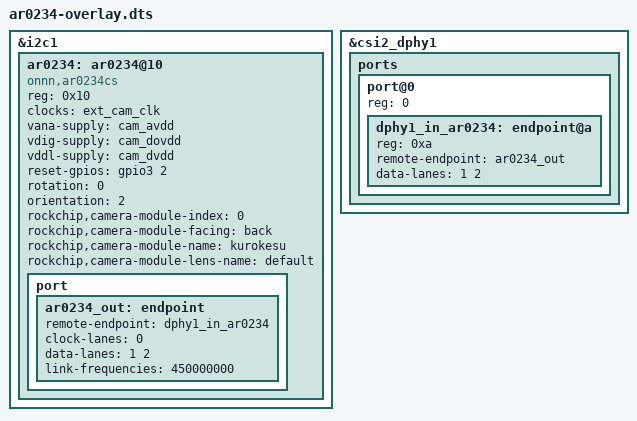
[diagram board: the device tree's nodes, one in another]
// SPDX-License-Identifier: GPL-2.0-only
/*
 * AR0234 (Kurokesu) on the LubanCat CSI0 connector - first bring-up overlay.
 *
 * Modelled on rk356x-lubancat-csi0-ov8858-1632x1224-30fps-overlay.dts, but
 * based on what rk3568-lubancat-csi2.dtsi really contains:
 *
 *   CSI0 = &i2c1 -> sensor -> &csi2_dphy1 (port@0, split mode, 2 lanes) -> rkisp_vir0
 *
 * Variant for the "csi2-double" dtsi (csi2_dphy0 disabled, csi2_dphy1 used).
 * For the single-camera dtsi use the overlay that targets &csi2_dphy0.
 *
 * A NEW sensor node is created instead of re-using the &ov8858 node, because
 * that node carries "lens-focus = <&dw9714>", which would make the sensor's
 * async notifier wait for a lens driver that this camera does not have.
 *
 * Labels referenced from the base device tree (all present in the dtsi):
 *   &i2c1 &csi2_dphy1 &ext_cam_clk &cam_avdd &cam_dovdd &cam_dvdd &gpio3
 *
 * Not verified on hardware.
 */
/dts-v1/;
/plugin/;

/ {
	fragment@0 {
		target = <&i2c1>;
		__overlay__ {
			/* Same values as the base i2c1 node; tells dtc that
			 * child "reg" is a 1-cell I2C address */
			#address-cells = <1>;
			#size-cells = <0>;
			status = "okay";

			ar0234: ar0234@10 {
				compatible = "onnn,ar0234cs";
				status = "okay";
				reg = <0x10>;

				/* 24 MHz fixed clock defined in the base dtsi */
				clocks = <&ext_cam_clk>;
				clock-names = "xvclk";

				/*
				 * Same rails the OV8858 node uses:
				 * avdd 2.8 V, dovdd 1.8 V, dvdd 1.2 V.
				 */
				vana-supply = <&cam_avdd>;
				vdig-supply = <&cam_dovdd>;
				vddl-supply = <&cam_dvdd>;

				/*
				 * Pin 11 of the 15-pin connector (CAM_IO0) is the
				 * module power enable and is wired to the board's
				 * CAM0_PWDN net. The driver drives its "reset" GPIO
				 * high while the sensor is powered, which is the
				 * level the module needs.
				 *
				 * <&gpio3 2 0> = GPIO3_A2, active high
				 * (2 = RK_PA2, 0 = GPIO_ACTIVE_HIGH; numbers are
				 * used because this overlay is built without the
				 * kernel include files).
				 * GPIO3_A2 = CAM0_PWDN, from the board schematic.
				 */
				reset-gpios = <&gpio3 2 0>;

				rotation = <0>;
				orientation = <2>;

				/* Rockchip module information (mandatory) */
				rockchip,camera-module-index = <0>;
				rockchip,camera-module-facing = "back";
				rockchip,camera-module-name = "kurokesu";
				rockchip,camera-module-lens-name = "default";

				port {
					ar0234_out: endpoint {
						remote-endpoint = <&dphy1_in_ar0234>;
						clock-lanes = <0>;
						data-lanes = <1 2>;
						/*
						 * The FIRST value selects the
						 * driver configuration:
						 *   450000000 -> 10-bit
						 *   360000000 ->  8-bit
						 */
						link-frequencies =
							/bits/ 64 <450000000>;
					};
				};
			};
		};
	};

	fragment@1 {
		target = <&csi2_dphy1>;
		__overlay__ {
			status = "okay";

			/* Same values as the base dtsi; needed so dtc
			 * accepts the 1-cell "reg" of port@0 / endpoint */
			ports {
				#address-cells = <1>;
				#size-cells = <0>;

				port@0 {
					reg = <0>;
					#address-cells = <1>;
					#size-cells = <0>;

					/* 0x1..0x9 are used by other sensors */
					dphy1_in_ar0234: endpoint@a {
						reg = <0xa>;
						remote-endpoint = <&ar0234_out>;
						data-lanes = <1 2>;
					};
				};
			};
		};
	};
};
